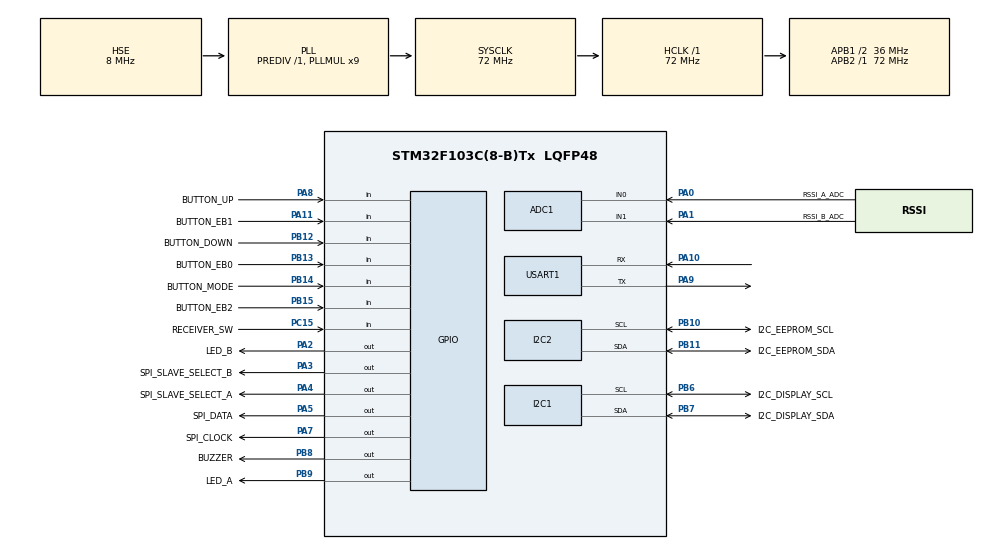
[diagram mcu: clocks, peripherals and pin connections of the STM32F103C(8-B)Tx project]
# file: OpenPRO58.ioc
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ADC1.Channel-0\#ChannelRegularConversion=ADC_CHANNEL_0
ADC1.Channel-1\#ChannelRegularConversion=ADC_CHANNEL_1
ADC1.ContinuousConvMode=ENABLE
ADC1.DataAlign=ADC_DATAALIGN_RIGHT
ADC1.DiscontinuousConvMode=DISABLE
ADC1.EnableAnalogWatchDog=false
ADC1.EnableRegularConversion=ENABLE
ADC1.ExternalTrigConvEdgeChoice=NONE
ADC1.InjNumberOfConversion=0
ADC1.NbrOfConversion=2
ADC1.NbrOfConversionFlag=1
ADC1.Rank-0\#ChannelRegularConversion=1
ADC1.Rank-1\#ChannelRegularConversion=2
ADC1.SamplingTime-0\#ChannelRegularConversion=ADC_SAMPLETIME_28CYCLES_5
ADC1.SamplingTime-1\#ChannelRegularConversion=ADC_SAMPLETIME_28CYCLES_5
ADC1.ScanConvMode=ADC_SCAN_ENABLE
ADC1.master=1
Dma.ADC1.0.Direction=DMA_PERIPH_TO_MEMORY
Dma.ADC1.0.Instance=DMA1_Channel1
Dma.ADC1.0.MemDataAlignment=DMA_MDATAALIGN_HALFWORD
Dma.ADC1.0.MemInc=DMA_MINC_ENABLE
Dma.ADC1.0.Mode=DMA_CIRCULAR
Dma.ADC1.0.PeriphDataAlignment=DMA_PDATAALIGN_HALFWORD
Dma.ADC1.0.PeriphInc=DMA_PINC_DISABLE
Dma.ADC1.0.Priority=DMA_PRIORITY_LOW
Dma.Request0=ADC1
I2C1.I2C_Mode=I2C_Fast
I2C2.I2C_Mode=I2C_Fast
Mcu.Family=STM32F1
Mcu.Name=STM32F103C(8-B)Tx
Mcu.Package=LQFP48
NVIC.DMA1_Channel1_IRQn=true\:0\:0\:false\:false\:true
NVIC.PriorityGroup=NVIC_PRIORITYGROUP_4
PA0-WKUP.GPIO_Label=RSSI_A_ADC
PA0-WKUP.Signal=ADCx_IN0
PA1.GPIO_Label=RSSI_B_ADC
PA1.Signal=ADCx_IN1
PA10.Mode=Asynchronous
PA10.Signal=USART1_RX
PA11.GPIO_Label=BUTTON_EB1
PA11.Signal=GPIO_Input
PA13.Mode=Serial_Wire
PA13.Signal=SYS_JTMS-SWDIO
PA14.Mode=Serial_Wire
PA14.Signal=SYS_JTCK-SWCLK
PA2.GPIO_Label=LED_B
PA2.Signal=GPIO_Output
PA3.GPIO_Label=SPI_SLAVE_SELECT_B
PA3.Signal=GPIO_Output
PA4.GPIO_Label=SPI_SLAVE_SELECT_A
PA4.Signal=GPIO_Output
PA5.GPIO_Label=SPI_DATA
PA5.Signal=GPIO_Output
PA7.GPIO_Label=SPI_CLOCK
PA7.Signal=GPIO_Output
PA8.GPIO_Label=BUTTON_UP
PA8.Signal=GPIO_Input
PA9.Mode=Asynchronous
PA9.Signal=USART1_TX
PB10.GPIO_Label=I2C_EEPROM_SCL
PB10.Mode=I2C
PB10.Signal=I2C2_SCL
PB11.GPIO_Label=I2C_EEPROM_SDA
PB11.Mode=I2C
PB11.Signal=I2C2_SDA
PB12.GPIO_Label=BUTTON_DOWN
PB12.Signal=GPIO_Input
PB13.GPIO_Label=BUTTON_EB0
PB13.Signal=GPIO_Input
PB14.GPIO_Label=BUTTON_MODE
PB14.Signal=GPIO_Input
PB15.GPIO_Label=BUTTON_EB2
PB15.Signal=GPIO_Input
PB6.GPIO_Label=I2C_DISPLAY_SCL
PB6.Mode=I2C
PB6.Signal=I2C1_SCL
PB7.GPIO_Label=I2C_DISPLAY_SDA
PB7.Mode=I2C
PB7.Signal=I2C1_SDA
PB8.GPIO_Label=BUZZER
PB8.Signal=GPIO_Output
PB9.GPIO_Label=LED_A
PB9.Signal=GPIO_Output
PC15-OSC32_OUT.GPIO_Label=RECEIVER_SW
PC15-OSC32_OUT.Signal=GPIO_Input
PD0-OSC_IN.Mode=HSE-External-Oscillator
PD0-OSC_IN.Signal=RCC_OSC_IN
PD1-OSC_OUT.Mode=HSE-External-Oscillator
PD1-OSC_OUT.Signal=RCC_OSC_OUT
ProjectManager.HeapSize=0x200
ProjectManager.StackSize=0x400
ProjectManager.TargetToolchain=SW4STM32
RCC.ADCPresc=RCC_ADCPCLK2_DIV6
RCC.AHBFreq_Value=72000000
RCC.APB1CLKDivider=RCC_HCLK_DIV2
RCC.APB1Freq_Value=36000000
RCC.APB1TimFreq_Value=72000000
RCC.APB2Freq_Value=72000000
RCC.APB2TimFreq_Value=72000000
RCC.HCLKFreq_Value=72000000
RCC.HSIState=RCC_HSI_ON
RCC.PLLMUL=RCC_PLL_MUL9
RCC.PLLSourceVirtual=RCC_PLLSOURCE_HSE
RCC.SYSCLKFreq_VALUE=72000000
RCC.SYSCLKSource=RCC_SYSCLKSOURCE_PLLCLK
RCC.USBFreq_Value=72000000
SH.ADCx_IN0.0=ADC1_IN0,IN0
SH.ADCx_IN1.0=ADC1_IN1,IN1
board=OpenPRO58

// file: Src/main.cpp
/**
  ******************************************************************************
  * File Name          : main.c
  * Description        : Main program body
  ******************************************************************************
  *
  * COPYRIGHT(c) 2017 STMicroelectronics
  *
  * Redistribution and use in source and binary forms, with or without modification,
  * are permitted provided that the following conditions are met:
  *   1. Redistributions of source code must retain the above copyright notice,
  *      this list of conditions and the following disclaimer.
  *   2. Redistributions in binary form must reproduce the above copyright notice,
  *      this list of conditions and the following disclaimer in the documentation
  *      and/or other materials provided with the distribution.
  *   3. Neither the name of STMicroelectronics nor the names of its contributors
  *      may be used to endorse or promote products derived from this software
  *      without specific prior written permission.
  *
  * THIS SOFTWARE IS PROVIDED BY THE COPYRIGHT HOLDERS AND CONTRIBUTORS "AS IS"
  * AND ANY EXPRESS OR IMPLIED WARRANTIES, INCLUDING, BUT NOT LIMITED TO, THE
  * IMPLIED WARRANTIES OF MERCHANTABILITY AND FITNESS FOR A PARTICULAR PURPOSE ARE
  * DISCLAIMED. IN NO EVENT SHALL THE COPYRIGHT HOLDER OR CONTRIBUTORS BE LIABLE
  * FOR ANY DIRECT, INDIRECT, INCIDENTAL, SPECIAL, EXEMPLARY, OR CONSEQUENTIAL
  * DAMAGES (INCLUDING, BUT NOT LIMITED TO, PROCUREMENT OF SUBSTITUTE GOODS OR
  * SERVICES; LOSS OF USE, DATA, OR PROFITS; OR BUSINESS INTERRUPTION) HOWEVER
  * CAUSED AND ON ANY THEORY OF LIABILITY, WHETHER IN CONTRACT, STRICT LIABILITY,
  * OR TORT (INCLUDING NEGLIGENCE OR OTHERWISE) ARISING IN ANY WAY OUT OF THE USE
  * OF THIS SOFTWARE, EVEN IF ADVISED OF THE POSSIBILITY OF SUCH DAMAGE.
  *
  ******************************************************************************
  */
#include "stm32f1xx_hal.h"

/* USER CODE BEGIN Includes */

#include "settings_eeprom.h"

/* USER CODE END Includes */

ADC_HandleTypeDef hadc1;
DMA_HandleTypeDef hdma_adc1;

I2C_HandleTypeDef hi2c1;
I2C_HandleTypeDef hi2c2;

UART_HandleTypeDef huart1;

/* USER CODE BEGIN PV */
/* Private variables ---------------------------------------------------------*/

/* USER CODE END PV */

void SystemClock_Config(void);
void Error_Handler(void);
static void MX_GPIO_Init(void);
static void MX_DMA_Init(void);
static void MX_ADC1_Init(void);
static void MX_I2C1_Init(void);
static void MX_I2C2_Init(void);
static void MX_USART1_UART_Init(void);

/* USER CODE BEGIN PFP */
/* Private function prototypes -----------------------------------------------*/

/* USER CODE END PFP */

int main(void)
{

  /* MCU Configuration----------------------------------------------------------*/

  /* Reset of all peripherals, Initializes the Flash interface and the Systick. */
  HAL_Init();

  /* Configure the system clock */
  SystemClock_Config();

  /* Initialize all configured peripherals */
  MX_GPIO_Init();
  MX_DMA_Init();
  MX_ADC1_Init();
  MX_I2C1_Init();
  MX_I2C2_Init();
  MX_USART1_UART_Init();

  /* USER CODE BEGIN 2 */

  HAL_GPIO_WritePin(RECEIVER_SW_GPIO_Port,RECEIVER_SW_Pin,GPIO_PIN_RESET);
  HAL_GPIO_WritePin(SPI_SLAVE_SELECT_A_GPIO_Port,SPI_SLAVE_SELECT_A_Pin,GPIO_PIN_SET);
  HAL_GPIO_WritePin(SPI_SLAVE_SELECT_B_GPIO_Port,SPI_SLAVE_SELECT_B_Pin,GPIO_PIN_SET);
  HAL_GPIO_WritePin(SPI_CLOCK_GPIO_Port,SPI_CLOCK_Pin,GPIO_PIN_RESET);
  HAL_GPIO_WritePin(SPI_DATA_GPIO_Port,SPI_DATA_Pin,GPIO_PIN_RESET);

  HAL_Delay(500); //Delay 500ms to allow RX5808 startup.

  EepromSettings.init(&hi2c2);
  EepromSettings.load();
  Receiver::setChannel(EepromSettings.startChannel);

  /* USER CODE END 2 */

  /* Infinite loop */
  while (1)
  {

  }

}

/** System Clock Configuration
*/
void SystemClock_Config(void)
{

  RCC_OscInitTypeDef RCC_OscInitStruct;
  RCC_ClkInitTypeDef RCC_ClkInitStruct;
  RCC_PeriphCLKInitTypeDef PeriphClkInit;

  RCC_OscInitStruct.OscillatorType = RCC_OSCILLATORTYPE_HSE;
  RCC_OscInitStruct.HSEState = RCC_HSE_ON;
  RCC_OscInitStruct.HSEPredivValue = RCC_HSE_PREDIV_DIV1;
  RCC_OscInitStruct.PLL.PLLState = RCC_PLL_ON;
  RCC_OscInitStruct.PLL.PLLSource = RCC_PLLSOURCE_HSE;
  RCC_OscInitStruct.PLL.PLLMUL = RCC_PLL_MUL9;
  if (HAL_RCC_OscConfig(&RCC_OscInitStruct) != HAL_OK)
  {
    Error_Handler();
  }

  RCC_ClkInitStruct.ClockType = RCC_CLOCKTYPE_HCLK|RCC_CLOCKTYPE_SYSCLK
                              |RCC_CLOCKTYPE_PCLK1|RCC_CLOCKTYPE_PCLK2;
  RCC_ClkInitStruct.SYSCLKSource = RCC_SYSCLKSOURCE_PLLCLK;
  RCC_ClkInitStruct.AHBCLKDivider = RCC_SYSCLK_DIV1;
  RCC_ClkInitStruct.APB1CLKDivider = RCC_HCLK_DIV2;
  RCC_ClkInitStruct.APB2CLKDivider = RCC_HCLK_DIV1;
  if (HAL_RCC_ClockConfig(&RCC_ClkInitStruct, FLASH_LATENCY_2) != HAL_OK)
  {
    Error_Handler();
  }

  PeriphClkInit.PeriphClockSelection = RCC_PERIPHCLK_ADC;
  PeriphClkInit.AdcClockSelection = RCC_ADCPCLK2_DIV6;
  if (HAL_RCCEx_PeriphCLKConfig(&PeriphClkInit) != HAL_OK)
  {
    Error_Handler();
  }

  HAL_SYSTICK_Config(HAL_RCC_GetHCLKFreq()/1000);

  HAL_SYSTICK_CLKSourceConfig(SYSTICK_CLKSOURCE_HCLK);

  /* SysTick_IRQn interrupt configuration */
  HAL_NVIC_SetPriority(SysTick_IRQn, 0, 0);
}

/* ADC1 init function */
static void MX_ADC1_Init(void)
{

  ADC_ChannelConfTypeDef sConfig;

    /**Common config
    */
  hadc1.Instance = ADC1;
  hadc1.Init.ScanConvMode = ADC_SCAN_ENABLE;
  hadc1.Init.ContinuousConvMode = ENABLE;
  hadc1.Init.DiscontinuousConvMode = DISABLE;
  hadc1.Init.ExternalTrigConv = ADC_SOFTWARE_START;
  hadc1.Init.DataAlign = ADC_DATAALIGN_RIGHT;
  hadc1.Init.NbrOfConversion = 2;
  if (HAL_ADC_Init(&hadc1) != HAL_OK)
  {
    Error_Handler();
  }

    /**Configure Regular Channel
    */
  sConfig.Channel = ADC_CHANNEL_0;
  sConfig.Rank = 1;
  sConfig.SamplingTime = ADC_SAMPLETIME_28CYCLES_5;
  if (HAL_ADC_ConfigChannel(&hadc1, &sConfig) != HAL_OK)
  {
    Error_Handler();
  }

    /**Configure Regular Channel
    */
  sConfig.Channel = ADC_CHANNEL_1;
  sConfig.Rank = 2;
  if (HAL_ADC_ConfigChannel(&hadc1, &sConfig) != HAL_OK)
  {
    Error_Handler();
  }

}

/* I2C1 init function */
static void MX_I2C1_Init(void)
{

  hi2c1.Instance = I2C1;
  hi2c1.Init.ClockSpeed = 400000;
  hi2c1.Init.DutyCycle = I2C_DUTYCYCLE_2;
  hi2c1.Init.OwnAddress1 = 0;
  hi2c1.Init.AddressingMode = I2C_ADDRESSINGMODE_7BIT;
  hi2c1.Init.DualAddressMode = I2C_DUALADDRESS_DISABLE;
  hi2c1.Init.OwnAddress2 = 0;
  hi2c1.Init.GeneralCallMode = I2C_GENERALCALL_DISABLE;
  hi2c1.Init.NoStretchMode = I2C_NOSTRETCH_DISABLE;
  if (HAL_I2C_Init(&hi2c1) != HAL_OK)
  {
    Error_Handler();
  }

}

/* I2C2 init function */
static void MX_I2C2_Init(void)
{

  hi2c2.Instance = I2C2;
  hi2c2.Init.ClockSpeed = 400000;
  hi2c2.Init.DutyCycle = I2C_DUTYCYCLE_2;
  hi2c2.Init.OwnAddress1 = 0;
  hi2c2.Init.AddressingMode = I2C_ADDRESSINGMODE_7BIT;
  hi2c2.Init.DualAddressMode = I2C_DUALADDRESS_DISABLE;
  hi2c2.Init.OwnAddress2 = 0;
  hi2c2.Init.GeneralCallMode = I2C_GENERALCALL_DISABLE;
  hi2c2.Init.NoStretchMode = I2C_NOSTRETCH_DISABLE;
  if (HAL_I2C_Init(&hi2c2) != HAL_OK)
  {
    Error_Handler();
  }

}

/* USART1 init function */
static void MX_USART1_UART_Init(void)
{

  huart1.Instance = USART1;
  huart1.Init.BaudRate = 115200;
  huart1.Init.WordLength = UART_WORDLENGTH_8B;
  huart1.Init.StopBits = UART_STOPBITS_1;
  huart1.Init.Parity = UART_PARITY_NONE;
  huart1.Init.Mode = UART_MODE_TX_RX;
  huart1.Init.HwFlowCtl = UART_HWCONTROL_NONE;
  huart1.Init.OverSampling = UART_OVERSAMPLING_16;
  if (HAL_UART_Init(&huart1) != HAL_OK)
  {
    Error_Handler();
  }

}

static void MX_DMA_Init(void)
{
  /* DMA controller clock enable */
  __HAL_RCC_DMA1_CLK_ENABLE();

  /* DMA interrupt init */
  /* DMA1_Channel1_IRQn interrupt configuration */
  HAL_NVIC_SetPriority(DMA1_Channel1_IRQn, 0, 0);
  HAL_NVIC_EnableIRQ(DMA1_Channel1_IRQn);

}

/** Configure pins as
        * Analog
        * Input
        * Output
        * EVENT_OUT
        * EXTI
*/
static void MX_GPIO_Init(void)
{

  GPIO_InitTypeDef GPIO_InitStruct;

  /* GPIO Ports Clock Enable */
  __HAL_RCC_GPIOC_CLK_ENABLE();
  __HAL_RCC_GPIOD_CLK_ENABLE();
  __HAL_RCC_GPIOA_CLK_ENABLE();
  __HAL_RCC_GPIOB_CLK_ENABLE();

  /*Configure GPIO pin : RECEIVER_SW_Pin */
  GPIO_InitStruct.Pin = RECEIVER_SW_Pin;
  GPIO_InitStruct.Mode = GPIO_MODE_INPUT;
  GPIO_InitStruct.Pull = GPIO_NOPULL;
  HAL_GPIO_Init(RECEIVER_SW_GPIO_Port, &GPIO_InitStruct);

  /*Configure GPIO pins : LED_B_Pin SPI_SLAVE_SELECT_B_Pin SPI_SLAVE_SELECT_A_Pin SPI_DATA_Pin
                           SPI_CLOCK_Pin */
  GPIO_InitStruct.Pin = LED_B_Pin|SPI_SLAVE_SELECT_B_Pin|SPI_SLAVE_SELECT_A_Pin|SPI_DATA_Pin
                          |SPI_CLOCK_Pin;
  GPIO_InitStruct.Mode = GPIO_MODE_OUTPUT_PP;
  GPIO_InitStruct.Speed = GPIO_SPEED_FREQ_LOW;
  HAL_GPIO_Init(GPIOA, &GPIO_InitStruct);

  /*Configure GPIO pins : BUTTON_DOWN_Pin BUTTON_EB0_Pin BUTTON_MODE_Pin BUTTON_EB2_Pin */
  GPIO_InitStruct.Pin = BUTTON_DOWN_Pin|BUTTON_EB0_Pin|BUTTON_MODE_Pin|BUTTON_EB2_Pin;
  GPIO_InitStruct.Mode = GPIO_MODE_INPUT;
  GPIO_InitStruct.Pull = GPIO_NOPULL;
  HAL_GPIO_Init(GPIOB, &GPIO_InitStruct);

  /*Configure GPIO pins : BUTTON_UP_Pin BUTTON_EB1_Pin */
  GPIO_InitStruct.Pin = BUTTON_UP_Pin|BUTTON_EB1_Pin;
  GPIO_InitStruct.Mode = GPIO_MODE_INPUT;
  GPIO_InitStruct.Pull = GPIO_NOPULL;
  HAL_GPIO_Init(GPIOA, &GPIO_InitStruct);

  /*Configure GPIO pins : BUZZER_Pin LED_A_Pin */
  GPIO_InitStruct.Pin = BUZZER_Pin|LED_A_Pin;
  GPIO_InitStruct.Mode = GPIO_MODE_OUTPUT_PP;
  GPIO_InitStruct.Speed = GPIO_SPEED_FREQ_LOW;
  HAL_GPIO_Init(GPIOB, &GPIO_InitStruct);

  /*Configure GPIO pin Output Level */
  HAL_GPIO_WritePin(GPIOA, LED_B_Pin|SPI_SLAVE_SELECT_B_Pin|SPI_SLAVE_SELECT_A_Pin|SPI_DATA_Pin
                          |SPI_CLOCK_Pin, GPIO_PIN_RESET);

  /*Configure GPIO pin Output Level */
  HAL_GPIO_WritePin(GPIOB, BUZZER_Pin|LED_A_Pin, GPIO_PIN_RESET);

}

void Error_Handler(void)
{
  while(1)
  {
  }
}

/************************ (C) COPYRIGHT STMicroelectronics *****END OF FILE****/
